AUTOSAR XML (schema 4-0-3)
package /AUTOSAR_FiM/ImplementationDataTypes
  impl type FunctionIdType: category=VALUE, base-type=uint8, range raw 1..9
package /AUTOSAR_FiM/SwComponentTypes
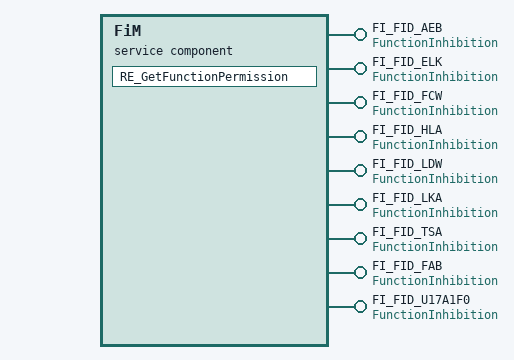
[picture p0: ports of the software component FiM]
  service sw component type FiM
    9 x provide port, all with server-com-spec{operation=GetFunctionPermission, queue-length=1}, provided-interface=FunctionInhibition:
      FI_FID_AEB
      FI_FID_ELK
      FI_FID_FCW
      FI_FID_HLA
      FI_FID_LDW
      FI_FID_LKA
      FI_FID_TSA
      FI_FID_FAB
      FI_FID_U17A1F0
    behavior FiMIntBeh: handle-termination-and-restart=NO-SUPPORT
      9 x operation invoked event, all with start-on-event=RE_GetFunctionPermission:
        EV_GetFunctionPermission_FID_AEB: operation=FI_FID_AEB.GetFunctionPermission
        EV_GetFunctionPermission_FID_ELK: operation=FI_FID_ELK.GetFunctionPermission
        EV_GetFunctionPermission_FID_FCW: operation=FI_FID_FCW.GetFunctionPermission
        EV_GetFunctionPermission_FID_HLA: operation=FI_FID_HLA.GetFunctionPermission
        EV_GetFunctionPermission_FID_LDW: operation=FI_FID_LDW.GetFunctionPermission
        EV_GetFunctionPermission_FID_LKA: operation=FI_FID_LKA.GetFunctionPermission
        EV_GetFunctionPermission_FID_TSA: operation=FI_FID_TSA.GetFunctionPermission
        EV_GetFunctionPermission_FID_FAB: operation=FI_FID_FAB.GetFunctionPermission
        EV_GetFunctionPermission_FID_U17A1F0: operation=FI_FID_U17A1F0.GetFunctionPermission
      port-api-options:
        {enable-take-address=false, indirect-api=false, port-defined-argument-value{value=1, value-type=FunctionIdType}, port=FI_FID_AEB}
        {enable-take-address=false, indirect-api=false, port-defined-argument-value{value=2, value-type=FunctionIdType}, port=FI_FID_ELK}
        {enable-take-address=false, indirect-api=false, port-defined-argument-value{value=3, value-type=FunctionIdType}, port=FI_FID_FCW}
        {enable-take-address=false, indirect-api=false, port-defined-argument-value{value=4, value-type=FunctionIdType}, port=FI_FID_HLA}
        {enable-take-address=false, indirect-api=false, port-defined-argument-value{value=5, value-type=FunctionIdType}, port=FI_FID_LDW}
        {enable-take-address=false, indirect-api=false, port-defined-argument-value{value=6, value-type=FunctionIdType}, port=FI_FID_LKA}
        {enable-take-address=false, indirect-api=false, port-defined-argument-value{value=7, value-type=FunctionIdType}, port=FI_FID_TSA}
        {enable-take-address=false, indirect-api=false, port-defined-argument-value{value=8, value-type=FunctionIdType}, port=FI_FID_FAB}
        {enable-take-address=false, indirect-api=false, port-defined-argument-value{value=9, value-type=FunctionIdType}, port=FI_FID_U17A1F0}
      runnable RE_GetFunctionPermission: arguments=[symbol=FID, symbol=Permission], can-be-invoked-concurrently=true, symbol=FiM_GetFunctionPermission
package /EB_FiM/SwcImplementations
  swc implementation SwcImplementation_0: programming-language=C, sw-version=2.5.4, vendor-id=1, behavior=FiMIntBeh
    code-descriptors:
      code FiMCode: artifact-descriptors=autosar-engineering-object={short-label=EngObject, category=SWSRC}
    resource consumption Resources
      memory section CODE: sw-addrmethod=CODE
